# XHSC_HC32L12X register map
Vendor: XHSC Co.Ltd; Series: ARMCM0P; File version: 1.0
CPU: CM0P r0p0, little endian, no MPU, no FPU, 3 interrupt priority bits
Registers are 32-bit, read-write, reset 0x0 unless marked. A register's access mark holds for its fields unless they carry their own. Offsets are from the block's base; [hi:lo] are bit positions; {n}, {i} and the like mark numbered series.

## I2C0 — desc I2C
Base 0x40000400
Same registers: I2C1 0x40008400
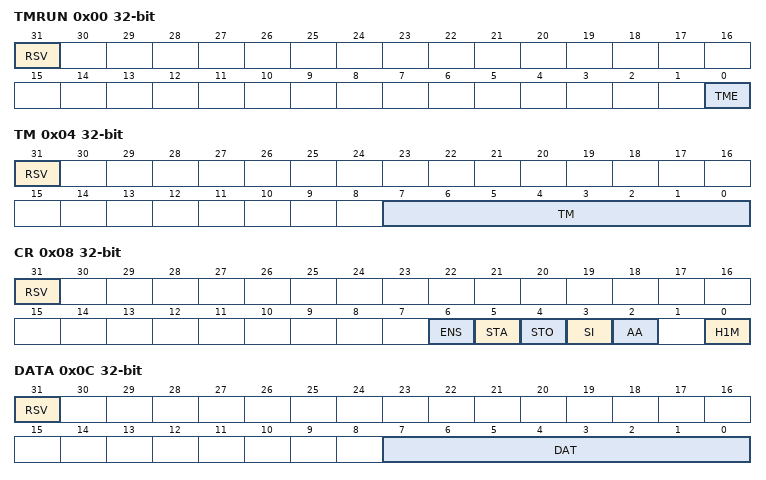
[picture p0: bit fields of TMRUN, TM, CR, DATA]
0x00 TMRUN (reset mask 0x1)
  [31] RSV, [0] TME
0x04 TM (reset mask 0xFF)
  [31] RSV, [7:0] TM
0x08 CR (reset mask 0x7D)
  [31] RSV, [6] ENS, [5] STA, [4] STO, [3] SI, [2] AA, [0] H1M
0x0C DATA (reset mask 0xFF)
  [31] RSV, [7:0] DAT
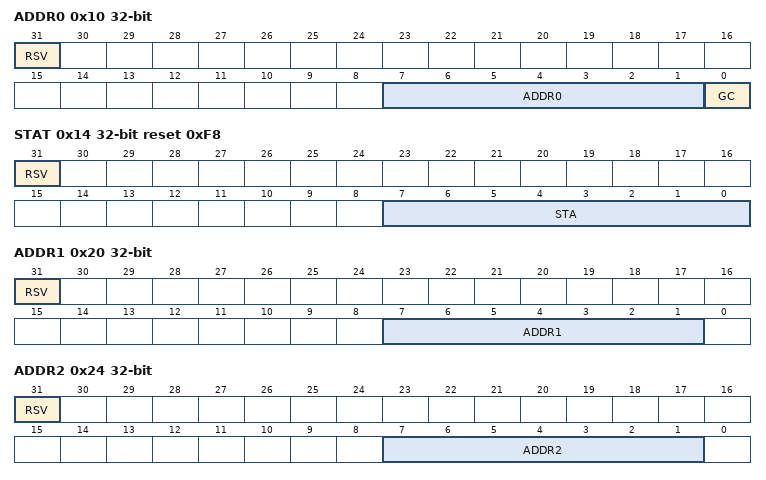
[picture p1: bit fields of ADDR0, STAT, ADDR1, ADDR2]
0x10 ADDR0 (reset mask 0xFF)
  [31] RSV, [7:1] ADDR0, [0] GC
0x14 STAT ro reset 0xF8 (reset mask 0xFF)
  [31] RSV rw, [7:0] STA
0x20 ADDR1 (reset mask 0xFE)
  [31] RSV, [7:1] ADDR1
0x24 ADDR2 (reset mask 0xFE)
  [31] RSV, [7:1] ADDR2
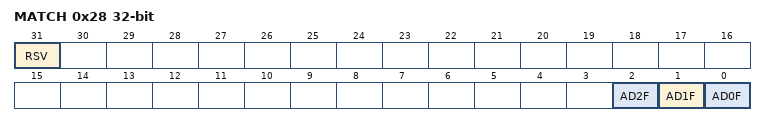
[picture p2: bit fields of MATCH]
0x28 MATCH ro (reset mask 0x7)
  [31] RSV, [2] AD2F, [1] AD1F, [0] AD0F

## IWDT
Base 0x40001080
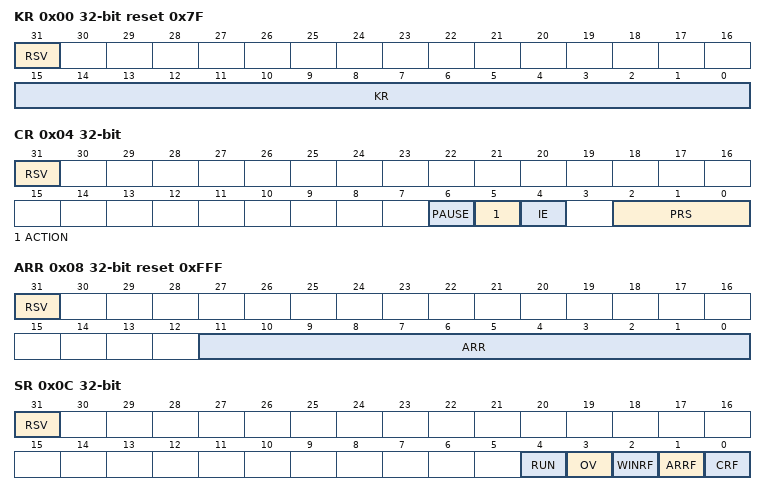
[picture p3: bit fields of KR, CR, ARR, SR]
0x00 KR wo reset 0x7F (reset mask 0xFFFF)
  [31] RSV, [15:0] KR
0x04 CR (reset mask 0x77)
  [31] RSV, [6] PAUSE, [5] ACTION, [4] IE, [2:0] PRS
0x08 ARR reset 0xFFF (reset mask 0xFFF)
  [31] RSV, [11:0] ARR
0x0C SR (reset mask 0x1F)
  [31] RSV ro, [4] RUN ro, [3] OV, [2] WINRF ro, [1] ARRF ro, [0] CRF ro
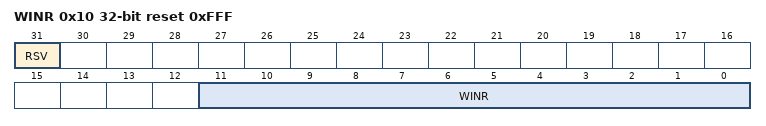
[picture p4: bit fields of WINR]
0x10 WINR reset 0xFFF (reset mask 0xFFF)
  [31] RSV, [11:0] WINR

## LCD
Base 0x40009C00
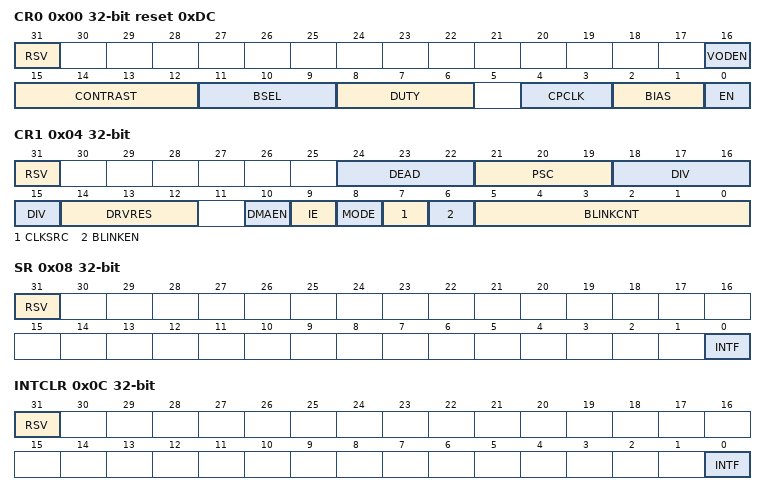
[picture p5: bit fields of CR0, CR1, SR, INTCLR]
0x00 CR0 reset 0xDC (reset mask 0x1FFFF)
  [31] RSV, [16] VODEN, [15:12] CONTRAST, [11:9] BSEL, [8:6] DUTY, [4:3] CPCLK, [2:1] BIAS, [0] EN
0x04 CR1 (reset mask 0x3FFF)
  [31] RSV ro, [24:22] DEAD, [21:19] PSC, [18:15] DIV, [14:12] DRVRES, [10] DMAEN, [9] IE, [8] MODE, [7] CLKSRC, [6] BLINKEN, [5:0] BLINKCNT
0x08 SR wo (reset mask 0x400)
  [31] RSV rw, [0] INTF
0x0C INTCLR wo (reset mask 0x400)
  [31] RSV rw, [0] INTF
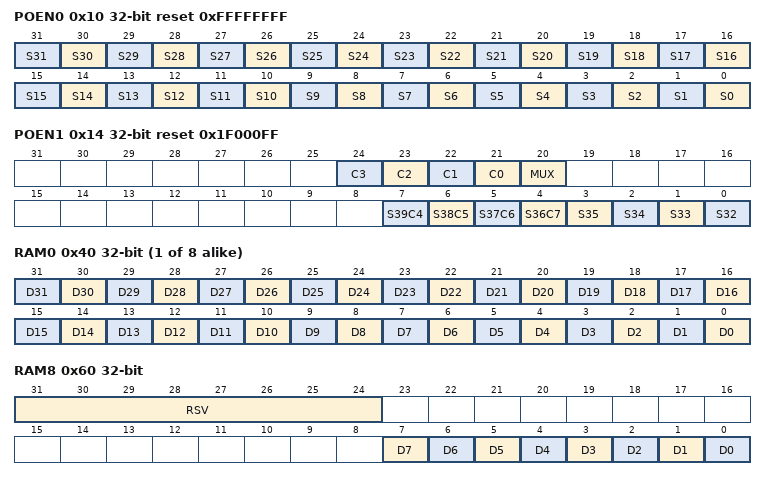
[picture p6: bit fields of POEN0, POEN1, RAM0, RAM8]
0x10 POEN0 reset 0xFFFFFFFF
  [n] S{n} (n=0..31)
0x14 POEN1 reset 0x1F000FF
  [n+21] C{n} (n=0..3), [20] MUX, [7] S39C4, [6] S38C5, [5] S37C6, [4] S36C7, [n-32] S{n} (n=32..35)
{0x40+4i} RAM{i} (i=0..7)
  [n] D{n} (n=0..31)
0x60 RAM8 (reset mask 0xFFFFFF)
  [31:24] RSV, [n] D{n} (n=0..7)
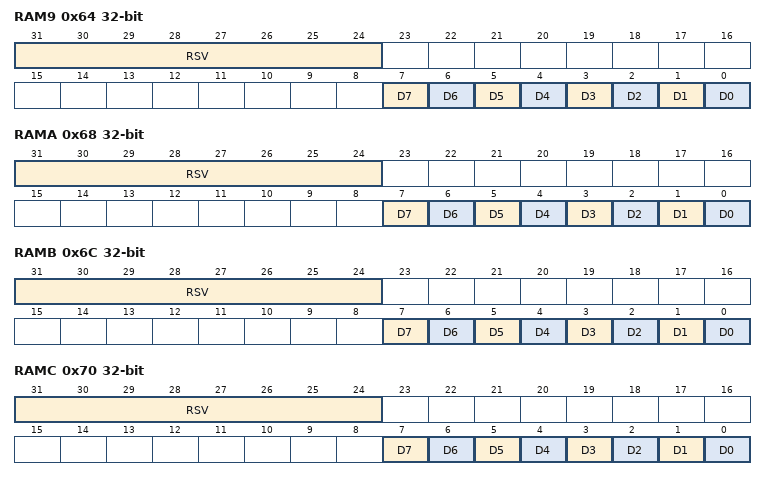
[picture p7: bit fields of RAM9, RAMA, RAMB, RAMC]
0x64 RAM9 (reset mask 0xFFFFFF)
  [31:24] RSV, [n] D{n} (n=0..7)
0x68 RAMA (reset mask 0xFFFFFF)
  [31:24] RSV, [n] D{n} (n=0..7)
0x6C RAMB (reset mask 0xFFFFFF)
  [31:24] RSV, [n] D{n} (n=0..7)
0x70 RAMC (reset mask 0xFFFFFF)
  [31:24] RSV, [n] D{n} (n=0..7)
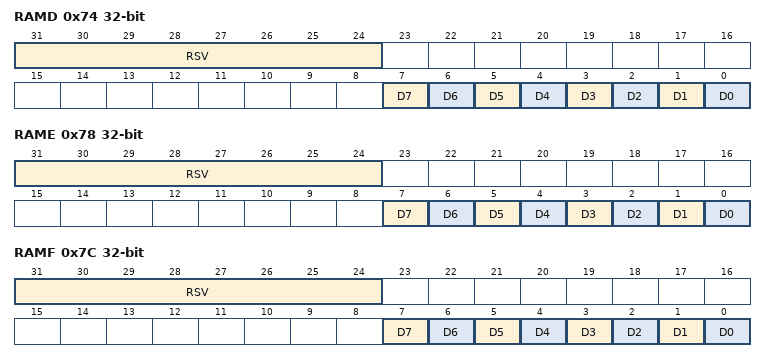
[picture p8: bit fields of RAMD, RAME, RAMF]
0x74 RAMD (reset mask 0xFFFFFF)
  [31:24] RSV, [n] D{n} (n=0..7)
0x78 RAME (reset mask 0xFFFFFF)
  [31:24] RSV, [n] D{n} (n=0..7)
0x7C RAMF (reset mask 0xFFFFFF)
  [31:24] RSV, [n] D{n} (n=0..7)

## LPTIMER0 — desc LPTIMER
Base 0x40000C00
Same registers: LPTIMER1 0x40003C00
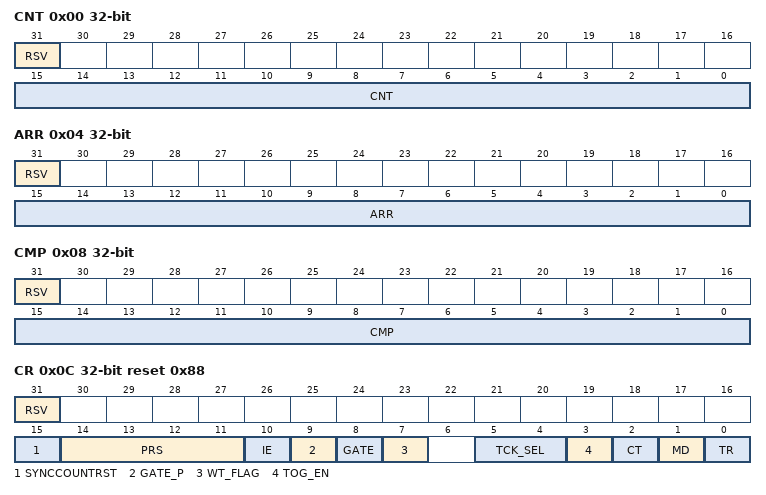
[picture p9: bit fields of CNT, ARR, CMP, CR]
0x00 CNT ro (reset mask 0xFFFF)
  [31] RSV rw, [15:0] CNT
0x04 ARR (reset mask 0xFFFF)
  [31] RSV, [15:0] ARR
0x08 CMP (reset mask 0xFFFF)
  [31] RSV, [15:0] CMP
0x0C CR reset 0x88 (reset mask 0x3FBF)
  [31] RSV, [15] SYNCCOUNTRST, [14:11] PRS, [10] IE, [9] GATE_P, [8] GATE, [7] WT_FLAG ro, [5:4] TCK_SEL, [3] TOG_EN, [2] CT, [1] MD, [0] TR
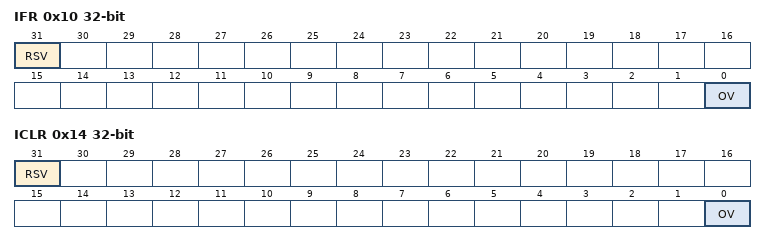
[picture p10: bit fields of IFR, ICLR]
0x10 IFR ro (reset mask 0x1)
  [31] RSV rw, [0] OV
0x14 ICLR wo (reset mask 0x1)
  [31] RSV rw, [0] OV

## LPUART0 — desc LPUART
Base 0x40000000
Same registers: LPUART1 0x40008000, LPUART2 0x4000B400
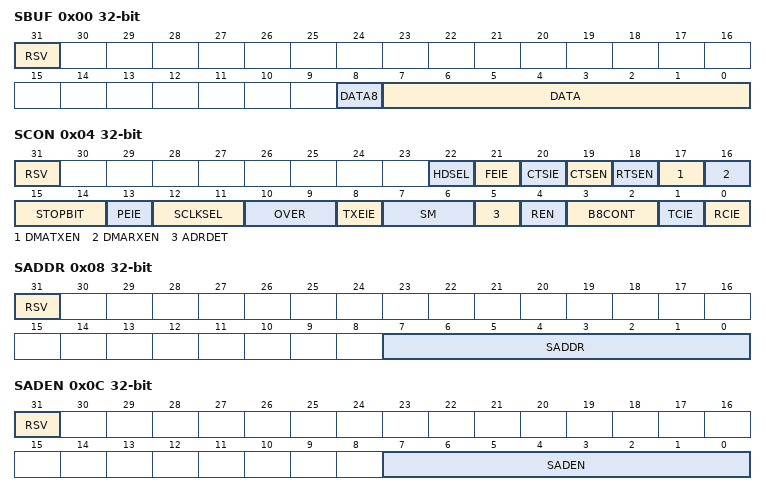
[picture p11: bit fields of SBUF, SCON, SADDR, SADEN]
0x00 SBUF (reset mask 0x1FF)
  [31] RSV, [8] DATA8, [7:0] DATA
0x04 SCON (reset mask 0x7FFFFF)
  [31] RSV, [22] HDSEL, [21] FEIE, [20] CTSIE, [19] CTSEN, [18] RTSEN, [17] DMATXEN, [16] DMARXEN, [15:14] STOPBIT, [13] PEIE, [12:11] SCLKSEL, [10:9] OVER, [8] TXEIE, [7:6] SM, [5] ADRDET, [4] REN, [3:2] B8CONT, [1] TCIE, [0] RCIE
0x08 SADDR (reset mask 0xFF)
  [31] RSV, [7:0] SADDR
0x0C SADEN (reset mask 0xFF)
  [31] RSV, [7:0] SADEN
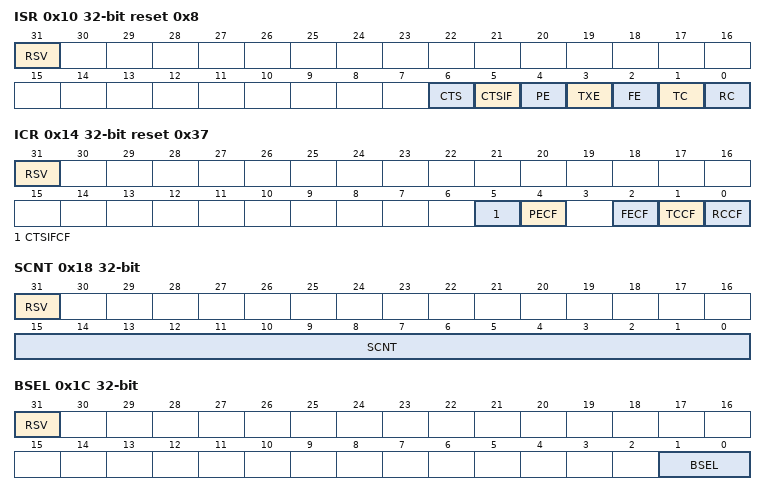
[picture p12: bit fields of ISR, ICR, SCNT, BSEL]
0x10 ISR ro reset 0x8 (reset mask 0x7F)
  [31] RSV rw, [6] CTS, [5] CTSIF, [4] PE, [3] TXE, [2] FE, [1] TC, [0] RC
0x14 ICR wo reset 0x37 (reset mask 0x37)
  [31] RSV rw, [5] CTSIFCF, [4] PECF, [2] FECF, [1] TCCF, [0] RCCF
0x18 SCNT (reset mask 0xFFFF)
  [31] RSV, [15:0] SCNT
0x1C BSEL (reset mask 0x3)
  [31] RSV, [1:0] BSEL
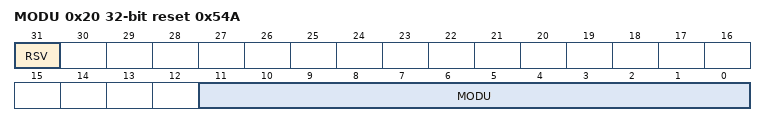
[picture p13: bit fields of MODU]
0x20 MODU reset 0x54A (reset mask 0xFFF)
  [31] RSV, [11:0] MODU
